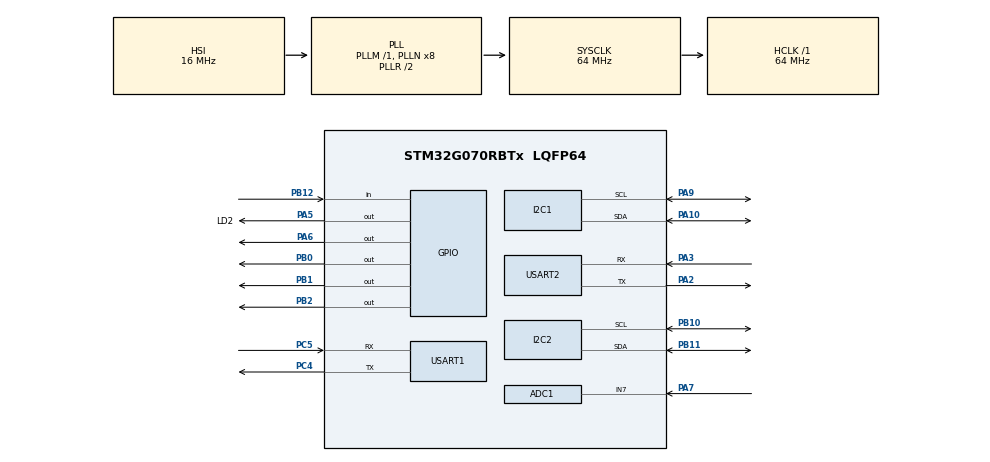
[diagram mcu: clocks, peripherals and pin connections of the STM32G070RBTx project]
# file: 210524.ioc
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ADC1.Channel-0\#ChannelRegularConversion=ADC_CHANNEL_7
ADC1.NbrOfConversionFlag=1
ADC1.Rank-0\#ChannelRegularConversion=1
ADC1.SamplingTime-0\#ChannelRegularConversion=ADC_SAMPLINGTIME_COMMON_1
ADC1.SelectedChannel=ADC_CHANNEL_7
ADC1.master=1
I2C1.Timing=0x10707DBC
I2C2.Timing=0x10707DBC
Mcu.Family=STM32G0
Mcu.Name=STM32G070RBTx
Mcu.Package=LQFP64
PA10.Mode=I2C
PA10.Signal=I2C1_SDA
PA2.Mode=Asynchronous
PA2.Signal=USART2_TX
PA3.Mode=Asynchronous
PA3.Signal=USART2_RX
PA5.GPIO_Label=LD2
PA5.Signal=GPIO_Output
PA6.Signal=GPIO_Output
PA7.Mode=IN7
PA7.Signal=ADC1_IN7
PA9.Mode=I2C
PA9.Signal=I2C1_SCL
PB0.Signal=GPIO_Output
PB1.Signal=GPIO_Output
PB10.Mode=I2C
PB10.Signal=I2C2_SCL
PB11.Mode=I2C
PB11.Signal=I2C2_SDA
PB12.Signal=GPIO_Input
PB2.Signal=GPIO_Output
PC4.Mode=Asynchronous
PC4.Signal=USART1_TX
PC5.Mode=Asynchronous
PC5.Signal=USART1_RX
ProjectManager.HeapSize=0x200
ProjectManager.StackSize=0x400
ProjectManager.TargetToolchain=STM32CubeIDE
RCC.ADCFreq_Value=64000000
RCC.AHBFreq_Value=64000000
RCC.CortexFreq_Value=64000000
RCC.EXTERNAL_CLOCK_VALUE=48000
RCC.HCLKFreq_Value=64000000
RCC.HSE_VALUE=8000000
RCC.HSI_VALUE=16000000
RCC.LSE_VALUE=32768
RCC.SYSCLKFreq_VALUE=64000000
RCC.SYSCLKSource=RCC_SYSCLKSOURCE_PLLCLK
RCC.VCOOutputFreq_Value=128000000
USART1.VirtualMode-Asynchronous=VM_ASYNC
USART2.VirtualMode-Asynchronous=VM_ASYNC
VP_SYS_VS_DBSignals.Mode=DisableDeadBatterySignals
board=custom

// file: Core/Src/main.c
/* USER CODE BEGIN Header */
/**
  ******************************************************************************
  * @file           : main.c
  * @brief          : Main program body
  ******************************************************************************
  * @attention
  *
  * <h2><center>&copy; Copyright (c) 2021 STMicroelectronics.
  * All rights reserved.</center></h2>
  *
  * This software component is licensed by ST under BSD 3-Clause license,
  * the "License"; You may not use this file except in compliance with the
  * License. You may obtain a copy of the License at:
  *                        opensource.org/licenses/BSD-3-Clause
  *
  ******************************************************************************
  */
/* USER CODE END Header */
#include "main.h"

/* USER CODE BEGIN PD */
#define LD2_Pin GPIO_PIN_5
#define LD2_GPIO_Port GPIOA
/* USER CODE END PD */

ADC_HandleTypeDef hadc1;

I2C_HandleTypeDef hi2c1;
I2C_HandleTypeDef hi2c2;

UART_HandleTypeDef huart1;
UART_HandleTypeDef huart2;

void SystemClock_Config(void);
static void MX_GPIO_Init(void);
static void MX_ADC1_Init(void);
static void MX_I2C1_Init(void);
static void MX_I2C2_Init(void);
static void MX_USART1_UART_Init(void);
static void MX_USART2_UART_Init(void);

int main(void)
{

  /* MCU Configuration--------------------------------------------------------*/

  /* Reset of all peripherals, Initializes the Flash interface and the Systick. */
  HAL_Init();

  /* Configure the system clock */
  SystemClock_Config();

  /* Initialize all configured peripherals */
  MX_GPIO_Init();
  MX_ADC1_Init();
  MX_I2C1_Init();
  MX_I2C2_Init();
  MX_USART1_UART_Init();
  MX_USART2_UART_Init();

  /* Infinite loop */
  /* USER CODE BEGIN WHILE */
  while (1)
  {
	  HAL_GPIO_TogglePin (LD2_GPIO_Port, LD2_Pin);
	  HAL_Delay(100);
	  //Test for Github
    /* USER CODE END WHILE */

  }
}

void SystemClock_Config(void)
{
  RCC_OscInitTypeDef RCC_OscInitStruct = {0};
  RCC_ClkInitTypeDef RCC_ClkInitStruct = {0};
  RCC_PeriphCLKInitTypeDef PeriphClkInit = {0};

  /** Configure the main internal regulator output voltage
  */
  HAL_PWREx_ControlVoltageScaling(PWR_REGULATOR_VOLTAGE_SCALE1);
  /** Initializes the RCC Oscillators according to the specified parameters
  * in the RCC_OscInitTypeDef structure.
  */
  RCC_OscInitStruct.OscillatorType = RCC_OSCILLATORTYPE_HSI;
  RCC_OscInitStruct.HSIState = RCC_HSI_ON;
  RCC_OscInitStruct.HSIDiv = RCC_HSI_DIV1;
  RCC_OscInitStruct.HSICalibrationValue = RCC_HSICALIBRATION_DEFAULT;
  RCC_OscInitStruct.PLL.PLLState = RCC_PLL_ON;
  RCC_OscInitStruct.PLL.PLLSource = RCC_PLLSOURCE_HSI;
  RCC_OscInitStruct.PLL.PLLM = RCC_PLLM_DIV1;
  RCC_OscInitStruct.PLL.PLLN = 8;
  RCC_OscInitStruct.PLL.PLLP = RCC_PLLP_DIV2;
  RCC_OscInitStruct.PLL.PLLR = RCC_PLLR_DIV2;
  if (HAL_RCC_OscConfig(&RCC_OscInitStruct) != HAL_OK)
  {
    Error_Handler();
  }
  /** Initializes the CPU, AHB and APB buses clocks
  */
  RCC_ClkInitStruct.ClockType = RCC_CLOCKTYPE_HCLK|RCC_CLOCKTYPE_SYSCLK
                              |RCC_CLOCKTYPE_PCLK1;
  RCC_ClkInitStruct.SYSCLKSource = RCC_SYSCLKSOURCE_PLLCLK;
  RCC_ClkInitStruct.AHBCLKDivider = RCC_SYSCLK_DIV1;
  RCC_ClkInitStruct.APB1CLKDivider = RCC_HCLK_DIV1;

  if (HAL_RCC_ClockConfig(&RCC_ClkInitStruct, FLASH_LATENCY_2) != HAL_OK)
  {
    Error_Handler();
  }
  /** Initializes the peripherals clocks
  */
  PeriphClkInit.PeriphClockSelection = RCC_PERIPHCLK_USART1|RCC_PERIPHCLK_USART2
                              |RCC_PERIPHCLK_I2C1|RCC_PERIPHCLK_ADC;
  PeriphClkInit.Usart1ClockSelection = RCC_USART1CLKSOURCE_PCLK1;
  PeriphClkInit.Usart2ClockSelection = RCC_USART2CLKSOURCE_PCLK1;
  PeriphClkInit.I2c1ClockSelection = RCC_I2C1CLKSOURCE_PCLK1;
  PeriphClkInit.AdcClockSelection = RCC_ADCCLKSOURCE_SYSCLK;
  if (HAL_RCCEx_PeriphCLKConfig(&PeriphClkInit) != HAL_OK)
  {
    Error_Handler();
  }
}

static void MX_ADC1_Init(void)
{

  ADC_ChannelConfTypeDef sConfig = {0};

  /** Configure the global features of the ADC (Clock, Resolution, Data Alignment and number of conversion)
  */
  hadc1.Instance = ADC1;
  hadc1.Init.ClockPrescaler = ADC_CLOCK_SYNC_PCLK_DIV2;
  hadc1.Init.Resolution = ADC_RESOLUTION_12B;
  hadc1.Init.DataAlign = ADC_DATAALIGN_RIGHT;
  hadc1.Init.ScanConvMode = ADC_SCAN_DISABLE;
  hadc1.Init.EOCSelection = ADC_EOC_SINGLE_CONV;
  hadc1.Init.LowPowerAutoWait = DISABLE;
  hadc1.Init.LowPowerAutoPowerOff = DISABLE;
  hadc1.Init.ContinuousConvMode = DISABLE;
  hadc1.Init.NbrOfConversion = 1;
  hadc1.Init.DiscontinuousConvMode = DISABLE;
  hadc1.Init.ExternalTrigConv = ADC_SOFTWARE_START;
  hadc1.Init.ExternalTrigConvEdge = ADC_EXTERNALTRIGCONVEDGE_NONE;
  hadc1.Init.DMAContinuousRequests = DISABLE;
  hadc1.Init.Overrun = ADC_OVR_DATA_PRESERVED;
  hadc1.Init.SamplingTimeCommon1 = ADC_SAMPLETIME_1CYCLE_5;
  hadc1.Init.SamplingTimeCommon2 = ADC_SAMPLETIME_1CYCLE_5;
  hadc1.Init.OversamplingMode = DISABLE;
  hadc1.Init.TriggerFrequencyMode = ADC_TRIGGER_FREQ_HIGH;
  if (HAL_ADC_Init(&hadc1) != HAL_OK)
  {
    Error_Handler();
  }
  /** Configure Regular Channel
  */
  sConfig.Channel = ADC_CHANNEL_7;
  sConfig.Rank = ADC_REGULAR_RANK_1;
  sConfig.SamplingTime = ADC_SAMPLINGTIME_COMMON_1;
  if (HAL_ADC_ConfigChannel(&hadc1, &sConfig) != HAL_OK)
  {
    Error_Handler();
  }

}

static void MX_I2C1_Init(void)
{

  hi2c1.Instance = I2C1;
  hi2c1.Init.Timing = 0x10707DBC;
  hi2c1.Init.OwnAddress1 = 0;
  hi2c1.Init.AddressingMode = I2C_ADDRESSINGMODE_7BIT;
  hi2c1.Init.DualAddressMode = I2C_DUALADDRESS_DISABLE;
  hi2c1.Init.OwnAddress2 = 0;
  hi2c1.Init.OwnAddress2Masks = I2C_OA2_NOMASK;
  hi2c1.Init.GeneralCallMode = I2C_GENERALCALL_DISABLE;
  hi2c1.Init.NoStretchMode = I2C_NOSTRETCH_DISABLE;
  if (HAL_I2C_Init(&hi2c1) != HAL_OK)
  {
    Error_Handler();
  }
  /** Configure Analogue filter
  */
  if (HAL_I2CEx_ConfigAnalogFilter(&hi2c1, I2C_ANALOGFILTER_ENABLE) != HAL_OK)
  {
    Error_Handler();
  }
  /** Configure Digital filter
  */
  if (HAL_I2CEx_ConfigDigitalFilter(&hi2c1, 0) != HAL_OK)
  {
    Error_Handler();
  }

}

static void MX_I2C2_Init(void)
{

  hi2c2.Instance = I2C2;
  hi2c2.Init.Timing = 0x10707DBC;
  hi2c2.Init.OwnAddress1 = 0;
  hi2c2.Init.AddressingMode = I2C_ADDRESSINGMODE_7BIT;
  hi2c2.Init.DualAddressMode = I2C_DUALADDRESS_DISABLE;
  hi2c2.Init.OwnAddress2 = 0;
  hi2c2.Init.OwnAddress2Masks = I2C_OA2_NOMASK;
  hi2c2.Init.GeneralCallMode = I2C_GENERALCALL_DISABLE;
  hi2c2.Init.NoStretchMode = I2C_NOSTRETCH_DISABLE;
  if (HAL_I2C_Init(&hi2c2) != HAL_OK)
  {
    Error_Handler();
  }
  /** Configure Analogue filter
  */
  if (HAL_I2CEx_ConfigAnalogFilter(&hi2c2, I2C_ANALOGFILTER_ENABLE) != HAL_OK)
  {
    Error_Handler();
  }
  /** Configure Digital filter
  */
  if (HAL_I2CEx_ConfigDigitalFilter(&hi2c2, 0) != HAL_OK)
  {
    Error_Handler();
  }

}

static void MX_USART1_UART_Init(void)
{

  huart1.Instance = USART1;
  huart1.Init.BaudRate = 115200;
  huart1.Init.WordLength = UART_WORDLENGTH_8B;
  huart1.Init.StopBits = UART_STOPBITS_1;
  huart1.Init.Parity = UART_PARITY_NONE;
  huart1.Init.Mode = UART_MODE_TX_RX;
  huart1.Init.HwFlowCtl = UART_HWCONTROL_NONE;
  huart1.Init.OverSampling = UART_OVERSAMPLING_16;
  huart1.Init.OneBitSampling = UART_ONE_BIT_SAMPLE_DISABLE;
  huart1.Init.ClockPrescaler = UART_PRESCALER_DIV1;
  huart1.AdvancedInit.AdvFeatureInit = UART_ADVFEATURE_NO_INIT;
  if (HAL_UART_Init(&huart1) != HAL_OK)
  {
    Error_Handler();
  }
  if (HAL_UARTEx_SetTxFifoThreshold(&huart1, UART_TXFIFO_THRESHOLD_1_8) != HAL_OK)
  {
    Error_Handler();
  }
  if (HAL_UARTEx_SetRxFifoThreshold(&huart1, UART_RXFIFO_THRESHOLD_1_8) != HAL_OK)
  {
    Error_Handler();
  }
  if (HAL_UARTEx_DisableFifoMode(&huart1) != HAL_OK)
  {
    Error_Handler();
  }

}

static void MX_USART2_UART_Init(void)
{

  huart2.Instance = USART2;
  huart2.Init.BaudRate = 115200;
  huart2.Init.WordLength = UART_WORDLENGTH_8B;
  huart2.Init.StopBits = UART_STOPBITS_1;
  huart2.Init.Parity = UART_PARITY_NONE;
  huart2.Init.Mode = UART_MODE_TX_RX;
  huart2.Init.HwFlowCtl = UART_HWCONTROL_NONE;
  huart2.Init.OverSampling = UART_OVERSAMPLING_16;
  huart2.Init.OneBitSampling = UART_ONE_BIT_SAMPLE_DISABLE;
  huart2.Init.ClockPrescaler = UART_PRESCALER_DIV1;
  huart2.AdvancedInit.AdvFeatureInit = UART_ADVFEATURE_NO_INIT;
  if (HAL_UART_Init(&huart2) != HAL_OK)
  {
    Error_Handler();
  }
  if (HAL_UARTEx_SetTxFifoThreshold(&huart2, UART_TXFIFO_THRESHOLD_1_8) != HAL_OK)
  {
    Error_Handler();
  }
  if (HAL_UARTEx_SetRxFifoThreshold(&huart2, UART_RXFIFO_THRESHOLD_1_8) != HAL_OK)
  {
    Error_Handler();
  }
  if (HAL_UARTEx_DisableFifoMode(&huart2) != HAL_OK)
  {
    Error_Handler();
  }

}

static void MX_GPIO_Init(void)
{
  GPIO_InitTypeDef GPIO_InitStruct = {0};

  /* GPIO Ports Clock Enable */
  __HAL_RCC_GPIOA_CLK_ENABLE();
  __HAL_RCC_GPIOC_CLK_ENABLE();
  __HAL_RCC_GPIOB_CLK_ENABLE();

  /*Configure GPIO pin Output Level */
  HAL_GPIO_WritePin(GPIOA, LD2_Pin|GPIO_PIN_6, GPIO_PIN_RESET);

  /*Configure GPIO pin Output Level */
  HAL_GPIO_WritePin(GPIOB, GPIO_PIN_0|GPIO_PIN_1|GPIO_PIN_2, GPIO_PIN_RESET);

  /*Configure GPIO pins : LD2_Pin PA6 */
  GPIO_InitStruct.Pin = LD2_Pin|GPIO_PIN_6;
  GPIO_InitStruct.Mode = GPIO_MODE_OUTPUT_PP;
  GPIO_InitStruct.Pull = GPIO_NOPULL;
  GPIO_InitStruct.Speed = GPIO_SPEED_FREQ_LOW;
  HAL_GPIO_Init(GPIOA, &GPIO_InitStruct);

  /*Configure GPIO pins : PB0 PB1 PB2 */
  GPIO_InitStruct.Pin = GPIO_PIN_0|GPIO_PIN_1|GPIO_PIN_2;
  GPIO_InitStruct.Mode = GPIO_MODE_OUTPUT_PP;
  GPIO_InitStruct.Pull = GPIO_NOPULL;
  GPIO_InitStruct.Speed = GPIO_SPEED_FREQ_LOW;
  HAL_GPIO_Init(GPIOB, &GPIO_InitStruct);

  /*Configure GPIO pin : PB12 */
  GPIO_InitStruct.Pin = GPIO_PIN_12;
  GPIO_InitStruct.Mode = GPIO_MODE_INPUT;
  GPIO_InitStruct.Pull = GPIO_NOPULL;
  HAL_GPIO_Init(GPIOB, &GPIO_InitStruct);

}

void Error_Handler(void)
{
  __disable_irq();
  while (1)
  {
  }
}

/************************ (C) COPYRIGHT STMicroelectronics *****END OF FILE****/
